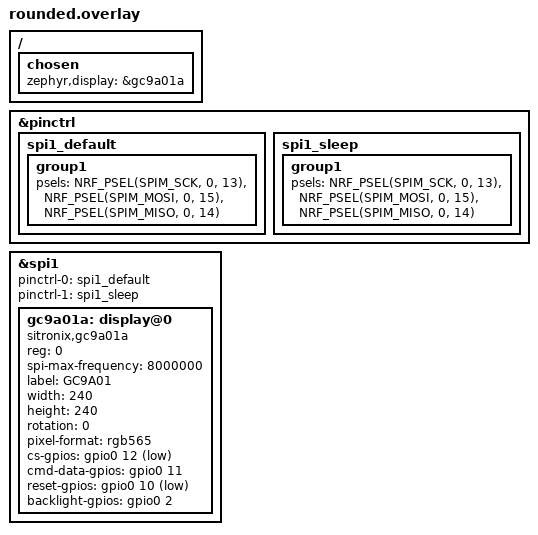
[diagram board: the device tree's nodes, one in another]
/ {
	chosen {
		zephyr,display = &gc9a01a;
	};
};

&pinctrl {
    spi1_default: spi1_default {
        group1 {
            psels = <NRF_PSEL(SPIM_SCK, 0, 13)>,
                    <NRF_PSEL(SPIM_MOSI, 0, 15)>,
                    <NRF_PSEL(SPIM_MISO, 0, 14)>;
        };
    };

    spi1_sleep: spi1_sleep {
        group1 {
            psels = <NRF_PSEL(SPIM_SCK, 0, 13)>,
                    <NRF_PSEL(SPIM_MOSI, 0, 15)>,
                    <NRF_PSEL(SPIM_MISO, 0, 14)>;
        };
    };
};

&spi1 {
    status = "okay";
    pinctrl-0 = <&spi1_default>;
    pinctrl-1 = <&spi1_sleep>;    /* satisfies the SPIM driver assertion */
    pinctrl-names = "default", "sleep";

    gc9a01a: display@0 {
        compatible = "sitronix,gc9a01a";
        reg = <0>;
        spi-max-frequency = <8000000>;
        label = "GC9A01";
        width = <240>;
        height = <240>;
        rotation = <0>;
        pixel-format = "rgb565";

        cs-gpios        = <&gpio0 12 GPIO_ACTIVE_LOW>;   /* CS */
        cmd-data-gpios  = <&gpio0 11 GPIO_ACTIVE_HIGH>;  /* DC */
        reset-gpios     = <&gpio0 10 GPIO_ACTIVE_LOW>;   /* RES */
        backlight-gpios = <&gpio0  2 GPIO_ACTIVE_HIGH>;  /* BLK */
    };
};
